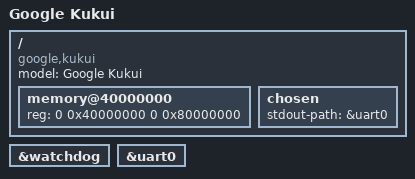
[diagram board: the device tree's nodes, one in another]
/dts-v1/;

#include <config.h>
#include "mt8183.dtsi"

/ {
	model = "Google Kukui";
	compatible = "google,kukui", "mediatek,mt8183";

	memory@40000000 {
		device_type = "memory";
		reg = <0 0x40000000 0 0x80000000>;
	};

	chosen {
		stdout-path = &uart0;
	};
};

&watchdog {
	status = "okay";
};

&uart0 {
	status = "okay";
};
